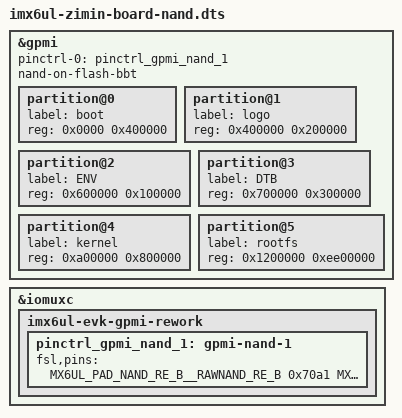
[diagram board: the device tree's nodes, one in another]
/*
 * Copyright (C) 2015 Freescale Semiconductor, Inc.
 *
 * This program is free software; you can redistribute it and/or modify
 * it under the terms of the GNU General Public License version 2 as
 * published by the Free Software Foundation.
 */

#include "imx6ul-zimin-board-emmc.dts"


&gpmi {
	pinctrl-names = "default";
	pinctrl-0 = <&pinctrl_gpmi_nand_1>;
	status = "okay";
	nand-on-flash-bbt;
	partition@0{
			label = "boot";
			reg = <0x0000 0x400000>; 
	};
	partition@1{
			label = "logo";
			reg = <0x400000 0x200000>;
	};
	partition@2{
			label = "ENV";
			reg = <0x600000 0x100000>; 
	};
	partition@3{
			label = "DTB";
			reg = <0x700000 0x300000>; 
	};
	partition@4{
			label = "kernel";
			reg = <0xa00000 0x800000>; 
	};
	partition@5{
			label = "rootfs";
			reg = <0x1200000 0xee00000>;
	};
};


&iomuxc {
	imx6ul-evk-gpmi-rework {
		pinctrl_gpmi_nand_1: gpmi-nand-1 {
			fsl,pins = <
					MX6UL_PAD_NAND_RE_B__RAWNAND_RE_B 0x70a1
					MX6UL_PAD_NAND_WE_B__RAWNAND_WE_B 0x70a1
					MX6UL_PAD_NAND_DATA00__RAWNAND_DATA00 0x70a1
					MX6UL_PAD_NAND_DATA01__RAWNAND_DATA01 0x70a1
					MX6UL_PAD_NAND_DATA02__RAWNAND_DATA02 0x70a1
					MX6UL_PAD_NAND_DATA03__RAWNAND_DATA03 0x70a1
					MX6UL_PAD_NAND_DATA04__RAWNAND_DATA04 0x70a1
					MX6UL_PAD_NAND_DATA05__RAWNAND_DATA05 0x70a1
					MX6UL_PAD_NAND_DATA06__RAWNAND_DATA06 0x70a1
					MX6UL_PAD_NAND_DATA07__RAWNAND_DATA07 0x70a1
					MX6UL_PAD_NAND_ALE__RAWNAND_ALE 0x70a1
					MX6UL_PAD_NAND_WP_B__RAWNAND_WP_B 0x70a1
					MX6UL_PAD_NAND_READY_B__RAWNAND_READY_B 0x70a1
					MX6UL_PAD_NAND_CE0_B__RAWNAND_CE0_B 0x70a1
					MX6UL_PAD_NAND_CLE__RAWNAND_CLE 0x70a1
			>;
		};
	};
};


/*
&gpmi {
	pinctrl-names = "default";
	pinctrl-0 = <&pinctrl_gpmi_nand_1>;
	status = "okay";
	nand-on-flash-bbt;
};

&iomuxc {
	pinctrl-names = "default";
	pinctrl-0 = <&pinctrl_hog_1>;
	imx6ul-evk {
		pinctrl_gpmi_nand_1: gpmi-nand-1 {
			fsl,pins = <
					MX6UL_PAD_NAND_RE_B__RAWNAND_RE_B 0x70a1
					MX6UL_PAD_NAND_WE_B__RAWNAND_WE_B 0x70a1
					MX6UL_PAD_NAND_DATA00__RAWNAND_DATA00 0x70a1
					MX6UL_PAD_NAND_DATA01__RAWNAND_DATA01 0x70a1
					MX6UL_PAD_NAND_DATA02__RAWNAND_DATA02 0x70a1
					MX6UL_PAD_NAND_DATA03__RAWNAND_DATA03 0x70a1
					MX6UL_PAD_NAND_DATA04__RAWNAND_DATA04 0x70a1
					MX6UL_PAD_NAND_DATA05__RAWNAND_DATA05 0x70a1
					MX6UL_PAD_NAND_DATA06__RAWNAND_DATA06 0x70a1
					MX6UL_PAD_NAND_DATA07__RAWNAND_DATA07 0x70a1
					MX6UL_PAD_NAND_ALE__RAWNAND_ALE 0x70a1
					MX6UL_PAD_NAND_WP_B__RAWNAND_WP_B 0x70a1
					MX6UL_PAD_NAND_READY_B__RAWNAND_READY_B 0x70a1
					MX6UL_PAD_NAND_CE0_B__RAWNAND_CE0_B 0x70a1
					MX6UL_PAD_NAND_CLE__RAWNAND_CLE 0x70a1
			>;
		};
	};
};
*/
